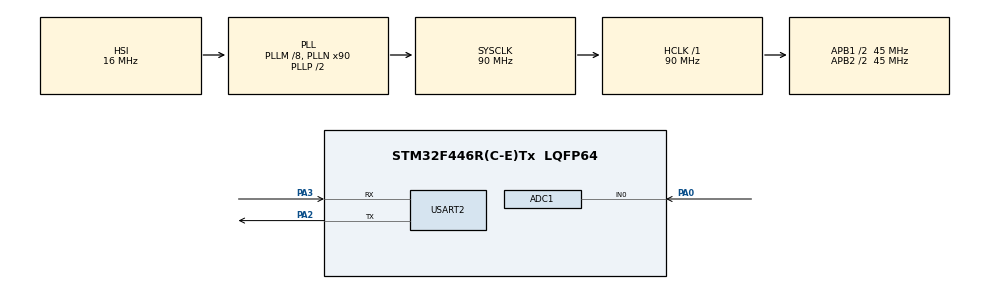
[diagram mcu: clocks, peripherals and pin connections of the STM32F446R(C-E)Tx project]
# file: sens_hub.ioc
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ADC1.Channel-0\#ChannelRegularConversion=ADC_CHANNEL_0
ADC1.ContinuousConvMode=DISABLE
ADC1.ExternalTrigConv=ADC_EXTERNALTRIGCONV_T2_TRGO
ADC1.NbrOfConversionFlag=1
ADC1.Rank-0\#ChannelRegularConversion=1
ADC1.Resolution=ADC_RESOLUTION_10B
ADC1.SamplingTime-0\#ChannelRegularConversion=ADC_SAMPLETIME_3CYCLES
ADC1.ScanConvMode=ENABLE
ADC1.master=1
Mcu.Family=STM32F4
Mcu.Name=STM32F446R(C-E)Tx
Mcu.Package=LQFP64
NVIC.ADC_IRQn=true\:0\:0\:false\:false\:true\:true\:true\:true
NVIC.PriorityGroup=NVIC_PRIORITYGROUP_4
NVIC.TIM2_IRQn=true\:0\:0\:false\:false\:true\:true\:true\:true
PA0-WKUP.Signal=ADCx_IN0
PA11.Signal=USB_OTG_FS_DM
PA12.Signal=USB_OTG_FS_DP
PA2.Mode=Asynchronous
PA2.Signal=USART2_TX
PA3.Mode=Asynchronous
PA3.Signal=USART2_RX
ProjectManager.HeapSize=0x200
ProjectManager.StackSize=0x400
ProjectManager.TargetToolchain=STM32CubeIDE
RCC.AHBFreq_Value=90000000
RCC.APB1CLKDivider=RCC_HCLK_DIV2
RCC.APB1Freq_Value=45000000
RCC.APB1TimFreq_Value=90000000
RCC.APB2CLKDivider=RCC_HCLK_DIV2
RCC.APB2Freq_Value=45000000
RCC.APB2TimFreq_Value=90000000
RCC.CortexFreq_Value=90000000
RCC.HCLKFreq_Value=90000000
RCC.PLLM=8
RCC.PLLN=90
RCC.SYSCLKFreq_VALUE=90000000
RCC.SYSCLKSource=RCC_SYSCLKSOURCE_PLLCLK
RCC.USBFreq_Value=90000000
RCC.VCOOutputFreq_Value=180000000
SH.ADCx_IN0.0=ADC1_IN0,IN0
TIM2.Period=5000
TIM2.Prescaler=9000
TIM2.TIM_MasterOutputTrigger=TIM_TRGO_UPDATE
USART2.VirtualMode=VM_ASYNC
VP_TIM2_VS_ClockSourceINT.Mode=Internal
board=custom

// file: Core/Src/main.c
/* USER CODE BEGIN Header */
/**
  ******************************************************************************
  * @file           : main.c
  * @brief          : Main program body
  ******************************************************************************
  * @attention
  *
  * Copyright (c) 2025 STMicroelectronics.
  * All rights reserved.
  *
  * This software is licensed under terms that can be found in the LICENSE file
  * in the root directory of this software component.
  * If no LICENSE file comes with this software, it is provided AS-IS.
  *
  ******************************************************************************
  */
/* USER CODE END Header */
#include "sens.h"
#include "main.h"
#include <stdio.h>

ADC_HandleTypeDef hadc1;

TIM_HandleTypeDef htim2;

UART_HandleTypeDef huart2;

void SystemClock_Config(void);
static void MX_GPIO_Init(void);
static void MX_ADC1_Init(void);
static void MX_TIM2_Init(void);
static void MX_USART2_UART_Init(void);

int main(void)
{

  /* MCU Configuration--------------------------------------------------------*/

  /* Reset of all peripherals, Initializes the Flash interface and the Systick. */
  HAL_Init();

  /* Configure the system clock */
  SystemClock_Config();

  /* Initialize all configured peripherals */
  MX_GPIO_Init();
  MX_ADC1_Init();
  MX_TIM2_Init();
  MX_USART2_UART_Init();
  /* USER CODE BEGIN 2 */
  HAL_TIM_Base_Start_IT(&htim2);
  HAL_ADC_Start(&hadc1);
  HAL_ADC_Start_IT(&hadc1);
  /* USER CODE END 2 */

  /* Infinite loop */
  while (1)
  {
	  if(adc1_flag)
	    {
		  adc1_flag = 0;
	      printf("adc_value -> %lu\r\n", adc1_value);
	    }
  }
}

void SystemClock_Config(void)
{
  RCC_OscInitTypeDef RCC_OscInitStruct = {0};
  RCC_ClkInitTypeDef RCC_ClkInitStruct = {0};

  /** Configure the main internal regulator output voltage
  */
  __HAL_RCC_PWR_CLK_ENABLE();
  __HAL_PWR_VOLTAGESCALING_CONFIG(PWR_REGULATOR_VOLTAGE_SCALE3);

  /** Initializes the RCC Oscillators according to the specified parameters
  * in the RCC_OscInitTypeDef structure.
  */
  RCC_OscInitStruct.OscillatorType = RCC_OSCILLATORTYPE_HSI;
  RCC_OscInitStruct.HSIState = RCC_HSI_ON;
  RCC_OscInitStruct.HSICalibrationValue = RCC_HSICALIBRATION_DEFAULT;
  RCC_OscInitStruct.PLL.PLLState = RCC_PLL_ON;
  RCC_OscInitStruct.PLL.PLLSource = RCC_PLLSOURCE_HSI;
  RCC_OscInitStruct.PLL.PLLM = 8;
  RCC_OscInitStruct.PLL.PLLN = 90;
  RCC_OscInitStruct.PLL.PLLP = RCC_PLLP_DIV2;
  RCC_OscInitStruct.PLL.PLLQ = 2;
  RCC_OscInitStruct.PLL.PLLR = 2;
  if (HAL_RCC_OscConfig(&RCC_OscInitStruct) != HAL_OK)
  {
    Error_Handler();
  }

  /** Initializes the CPU, AHB and APB buses clocks
  */
  RCC_ClkInitStruct.ClockType = RCC_CLOCKTYPE_HCLK|RCC_CLOCKTYPE_SYSCLK
                              |RCC_CLOCKTYPE_PCLK1|RCC_CLOCKTYPE_PCLK2;
  RCC_ClkInitStruct.SYSCLKSource = RCC_SYSCLKSOURCE_PLLCLK;
  RCC_ClkInitStruct.AHBCLKDivider = RCC_SYSCLK_DIV1;
  RCC_ClkInitStruct.APB1CLKDivider = RCC_HCLK_DIV2;
  RCC_ClkInitStruct.APB2CLKDivider = RCC_HCLK_DIV2;

  if (HAL_RCC_ClockConfig(&RCC_ClkInitStruct, FLASH_LATENCY_2) != HAL_OK)
  {
    Error_Handler();
  }
}

static void MX_ADC1_Init(void)
{

  ADC_ChannelConfTypeDef sConfig = {0};

  /** Configure the global features of the ADC (Clock, Resolution, Data Alignment and number of conversion)
  */
  hadc1.Instance = ADC1;
  hadc1.Init.ClockPrescaler = ADC_CLOCK_SYNC_PCLK_DIV2;
  hadc1.Init.Resolution = ADC_RESOLUTION_10B;
  hadc1.Init.ScanConvMode = ENABLE;
  hadc1.Init.ContinuousConvMode = DISABLE;
  hadc1.Init.DiscontinuousConvMode = DISABLE;
  hadc1.Init.ExternalTrigConvEdge = ADC_EXTERNALTRIGCONVEDGE_RISING;
  hadc1.Init.ExternalTrigConv = ADC_EXTERNALTRIGCONV_T2_TRGO;
  hadc1.Init.DataAlign = ADC_DATAALIGN_RIGHT;
  hadc1.Init.NbrOfConversion = 1;
  hadc1.Init.DMAContinuousRequests = DISABLE;
  hadc1.Init.EOCSelection = ADC_EOC_SINGLE_CONV;
  if (HAL_ADC_Init(&hadc1) != HAL_OK)
  {
    Error_Handler();
  }

  /** Configure for the selected ADC regular channel its corresponding rank in the sequencer and its sample time.
  */
  sConfig.Channel = ADC_CHANNEL_0;
  sConfig.Rank = 1;
  sConfig.SamplingTime = ADC_SAMPLETIME_3CYCLES;
  if (HAL_ADC_ConfigChannel(&hadc1, &sConfig) != HAL_OK)
  {
    Error_Handler();
  }

}

static void MX_TIM2_Init(void)
{

  TIM_ClockConfigTypeDef sClockSourceConfig = {0};
  TIM_MasterConfigTypeDef sMasterConfig = {0};

  htim2.Instance = TIM2;
  htim2.Init.Prescaler = 9000;
  htim2.Init.CounterMode = TIM_COUNTERMODE_UP;
  htim2.Init.Period = 5000;
  htim2.Init.ClockDivision = TIM_CLOCKDIVISION_DIV1;
  htim2.Init.AutoReloadPreload = TIM_AUTORELOAD_PRELOAD_DISABLE;
  if (HAL_TIM_Base_Init(&htim2) != HAL_OK)
  {
    Error_Handler();
  }
  sClockSourceConfig.ClockSource = TIM_CLOCKSOURCE_INTERNAL;
  if (HAL_TIM_ConfigClockSource(&htim2, &sClockSourceConfig) != HAL_OK)
  {
    Error_Handler();
  }
  sMasterConfig.MasterOutputTrigger = TIM_TRGO_UPDATE;
  sMasterConfig.MasterSlaveMode = TIM_MASTERSLAVEMODE_DISABLE;
  if (HAL_TIMEx_MasterConfigSynchronization(&htim2, &sMasterConfig) != HAL_OK)
  {
    Error_Handler();
  }

}

static void MX_USART2_UART_Init(void)
{

  huart2.Instance = USART2;
  huart2.Init.BaudRate = 115200;
  huart2.Init.WordLength = UART_WORDLENGTH_8B;
  huart2.Init.StopBits = UART_STOPBITS_1;
  huart2.Init.Parity = UART_PARITY_NONE;
  huart2.Init.Mode = UART_MODE_TX_RX;
  huart2.Init.HwFlowCtl = UART_HWCONTROL_NONE;
  huart2.Init.OverSampling = UART_OVERSAMPLING_16;
  if (HAL_UART_Init(&huart2) != HAL_OK)
  {
    Error_Handler();
  }

}

static void MX_GPIO_Init(void)
{
  GPIO_InitTypeDef GPIO_InitStruct = {0};

  /* GPIO Ports Clock Enable */
  __HAL_RCC_GPIOA_CLK_ENABLE();

  /*Configure GPIO pins : PA11 PA12 */
  GPIO_InitStruct.Pin = GPIO_PIN_11|GPIO_PIN_12;
  GPIO_InitStruct.Mode = GPIO_MODE_AF_PP;
  GPIO_InitStruct.Pull = GPIO_NOPULL;
  GPIO_InitStruct.Speed = GPIO_SPEED_FREQ_VERY_HIGH;
  GPIO_InitStruct.Alternate = GPIO_AF10_OTG_FS;
  HAL_GPIO_Init(GPIOA, &GPIO_InitStruct);

}

void Error_Handler(void)
{
  __disable_irq();
  while (1)
  {
  }
}
